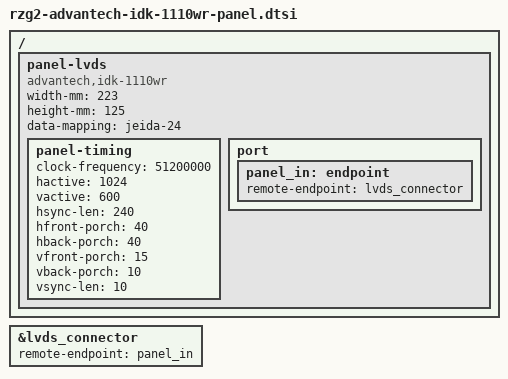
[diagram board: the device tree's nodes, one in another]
// SPDX-License-Identifier: GPL-2.0
/*
 * Device Tree Source for the Advantech idk-1110wr LVDS panel connected
 * to RZ/G2 boards
 *
 * Copyright (C) 2019 Renesas Electronics Corp.
 */

/ {
	panel-lvds {
		compatible = "advantech,idk-1110wr", "panel-lvds";

		width-mm = <223>;
		height-mm = <125>;

		data-mapping = "jeida-24";

		panel-timing {
			/* 1024x600 @60Hz */
			clock-frequency = <51200000>;
			hactive = <1024>;
			vactive = <600>;
			hsync-len = <240>;
			hfront-porch = <40>;
			hback-porch = <40>;
			vfront-porch = <15>;
			vback-porch = <10>;
			vsync-len = <10>;
		};

		port {
			panel_in: endpoint {
				remote-endpoint = <&lvds_connector>;
			};
		};
	};
};

&lvds_connector {
	remote-endpoint = <&panel_in>;
};
